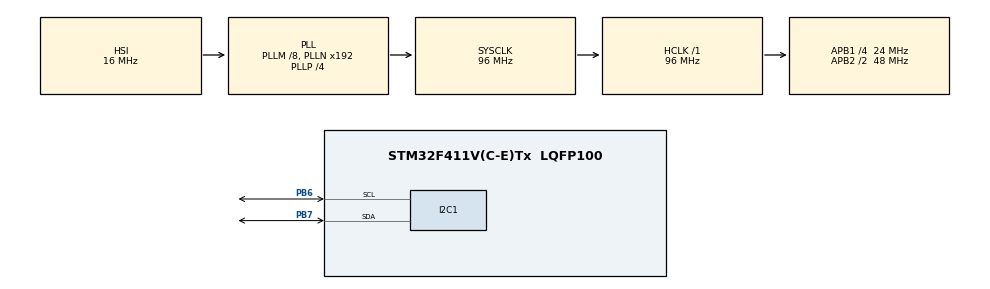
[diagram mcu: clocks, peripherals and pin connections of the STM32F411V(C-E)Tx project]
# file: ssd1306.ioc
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Mcu.Family=STM32F4
Mcu.Name=STM32F411V(C-E)Tx
Mcu.Package=LQFP100
NVIC.PriorityGroup=NVIC_PRIORITYGROUP_0
PB6.Mode=I2C
PB6.Signal=I2C1_SCL
PB7.Mode=I2C
PB7.Signal=I2C1_SDA
ProjectManager.HeapSize=0x400
ProjectManager.StackSize=0x200
ProjectManager.TargetToolchain=SW4STM32
RCC.48MHZClocksFreq_Value=48000000
RCC.AHBFreq_Value=96000000
RCC.APB1CLKDivider=RCC_HCLK_DIV4
RCC.APB1Freq_Value=24000000
RCC.APB1TimFreq_Value=48000000
RCC.APB2CLKDivider=RCC_HCLK_DIV2
RCC.APB2Freq_Value=48000000
RCC.APB2TimFreq_Value=96000000
RCC.CortexFreq_Value=96000000
RCC.HCLKFreq_Value=96000000
RCC.HSE_VALUE=8000000
RCC.HSI_VALUE=16000000
RCC.LSE_VALUE=32768
RCC.PLLI2SM=5
RCC.PLLI2SN=200
RCC.PLLM=8
RCC.PLLP=RCC_PLLP_DIV4
RCC.PLLQ=8
RCC.SYSCLKFreq_VALUE=96000000
RCC.SYSCLKSource=RCC_SYSCLKSOURCE_PLLCLK
RCC.VCOOutputFreq_Value=384000000
board=STM32F411E-DISCO

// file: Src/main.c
/**
  ******************************************************************************
  * File Name          : main.c
  * Description        : Main program body
  ******************************************************************************
  *
  * COPYRIGHT(c) 2016 STMicroelectronics
  *
  * Redistribution and use in source and binary forms, with or without modification,
  * are permitted provided that the following conditions are met:
  *   1. Redistributions of source code must retain the above copyright notice,
  *      this list of conditions and the following disclaimer.
  *   2. Redistributions in binary form must reproduce the above copyright notice,
  *      this list of conditions and the following disclaimer in the documentation
  *      and/or other materials provided with the distribution.
  *   3. Neither the name of STMicroelectronics nor the names of its contributors
  *      may be used to endorse or promote products derived from this software
  *      without specific prior written permission.
  *
  * THIS SOFTWARE IS PROVIDED BY THE COPYRIGHT HOLDERS AND CONTRIBUTORS "AS IS"
  * AND ANY EXPRESS OR IMPLIED WARRANTIES, INCLUDING, BUT NOT LIMITED TO, THE
  * IMPLIED WARRANTIES OF MERCHANTABILITY AND FITNESS FOR A PARTICULAR PURPOSE ARE
  * DISCLAIMED. IN NO EVENT SHALL THE COPYRIGHT HOLDER OR CONTRIBUTORS BE LIABLE
  * FOR ANY DIRECT, INDIRECT, INCIDENTAL, SPECIAL, EXEMPLARY, OR CONSEQUENTIAL
  * DAMAGES (INCLUDING, BUT NOT LIMITED TO, PROCUREMENT OF SUBSTITUTE GOODS OR
  * SERVICES; LOSS OF USE, DATA, OR PROFITS; OR BUSINESS INTERRUPTION) HOWEVER
  * CAUSED AND ON ANY THEORY OF LIABILITY, WHETHER IN CONTRACT, STRICT LIABILITY,
  * OR TORT (INCLUDING NEGLIGENCE OR OTHERWISE) ARISING IN ANY WAY OUT OF THE USE
  * OF THIS SOFTWARE, EVEN IF ADVISED OF THE POSSIBILITY OF SUCH DAMAGE.
  *
  ******************************************************************************
  */
#include "stm32f4xx_hal.h"

/* USER CODE BEGIN Includes */

#include "ssd1306.h"
#include "fonts.h"

/* USER CODE END Includes */

I2C_HandleTypeDef hi2c1;

/* USER CODE BEGIN PV */
/* Private variables ---------------------------------------------------------*/

/* USER CODE END PV */

void SystemClock_Config(void);
static void MX_GPIO_Init(void);
static void MX_I2C1_Init(void);

/* USER CODE BEGIN PFP */
/* Private function prototypes -----------------------------------------------*/

/* USER CODE END PFP */

int main(void)
{

  /* MCU Configuration----------------------------------------------------------*/

  /* Reset of all peripherals, Initializes the Flash interface and the Systick. */
  HAL_Init();

  /* Configure the system clock */
  SystemClock_Config();

  /* Initialize all configured peripherals */
  MX_GPIO_Init();
  MX_I2C1_Init();

  /* USER CODE BEGIN 2 */

  ssd1306_Init();
  HAL_Delay(1000);
  ssd1306_Fill(White);
  ssd1306_UpdateScreen();

  HAL_Delay(1000);

  ssd1306_SetCursor(23,23);
  ssd1306_WriteString("4ilo",Font_11x18,Black);

  ssd1306_UpdateScreen();

  /* USER CODE END 2 */

  /* Infinite loop */
  while (1)
  {

  }

}

/** System Clock Configuration
*/
void SystemClock_Config(void)
{

  RCC_OscInitTypeDef RCC_OscInitStruct;
  RCC_ClkInitTypeDef RCC_ClkInitStruct;

  __PWR_CLK_ENABLE();

  __HAL_PWR_VOLTAGESCALING_CONFIG(PWR_REGULATOR_VOLTAGE_SCALE1);

  RCC_OscInitStruct.OscillatorType = RCC_OSCILLATORTYPE_HSI;
  RCC_OscInitStruct.HSIState = RCC_HSI_ON;
  RCC_OscInitStruct.HSICalibrationValue = 16;
  RCC_OscInitStruct.PLL.PLLState = RCC_PLL_ON;
  RCC_OscInitStruct.PLL.PLLSource = RCC_PLLSOURCE_HSI;
  RCC_OscInitStruct.PLL.PLLM = 8;
  RCC_OscInitStruct.PLL.PLLN = 192;
  RCC_OscInitStruct.PLL.PLLP = RCC_PLLP_DIV4;
  RCC_OscInitStruct.PLL.PLLQ = 8;
  HAL_RCC_OscConfig(&RCC_OscInitStruct);

  RCC_ClkInitStruct.ClockType = RCC_CLOCKTYPE_HCLK|RCC_CLOCKTYPE_SYSCLK
                              |RCC_CLOCKTYPE_PCLK1|RCC_CLOCKTYPE_PCLK2;
  RCC_ClkInitStruct.SYSCLKSource = RCC_SYSCLKSOURCE_PLLCLK;
  RCC_ClkInitStruct.AHBCLKDivider = RCC_SYSCLK_DIV1;
  RCC_ClkInitStruct.APB1CLKDivider = RCC_HCLK_DIV4;
  RCC_ClkInitStruct.APB2CLKDivider = RCC_HCLK_DIV2;
  HAL_RCC_ClockConfig(&RCC_ClkInitStruct, FLASH_LATENCY_3);

  HAL_SYSTICK_Config(HAL_RCC_GetHCLKFreq()/1000);

  HAL_SYSTICK_CLKSourceConfig(SYSTICK_CLKSOURCE_HCLK);

  /* SysTick_IRQn interrupt configuration */
  HAL_NVIC_SetPriority(SysTick_IRQn, 0, 0);
}

/* I2C1 init function */
void MX_I2C1_Init(void)
{

  hi2c1.Instance = I2C1;
  hi2c1.Init.ClockSpeed = 100000;
  hi2c1.Init.DutyCycle = I2C_DUTYCYCLE_2;
  hi2c1.Init.OwnAddress1 = 0;
  hi2c1.Init.AddressingMode = I2C_ADDRESSINGMODE_7BIT;
  hi2c1.Init.DualAddressMode = I2C_DUALADDRESS_DISABLED;
  hi2c1.Init.OwnAddress2 = 0;
  hi2c1.Init.GeneralCallMode = I2C_GENERALCALL_DISABLED;
  hi2c1.Init.NoStretchMode = I2C_NOSTRETCH_DISABLED;
  HAL_I2C_Init(&hi2c1);

}

/** Pinout Configuration
*/
void MX_GPIO_Init(void)
{

  /* GPIO Ports Clock Enable */
  __GPIOB_CLK_ENABLE();

}

/************************ (C) COPYRIGHT STMicroelectronics *****END OF FILE****/
